# RE01_256KB register map
Vendor: Renesas Electronics Corporation; Series: RE01; File version: 1.00.01
CPU: CM0PLUS r0p1, little endian, MPU, no FPU, VTOR, 2 interrupt priority bits, 32 interrupts
Registers are 8-bit, read-write, reset 0x0 unless marked. A register's access mark holds for its fields unless they carry their own. Offsets are from the block's base; [hi:lo] are bit positions; {n}, {i} and the like mark numbered series; 'fields as' and 'values as' point back to an identical list.

## PORT2 — Port 2 Control Registers
Base 0x40040040
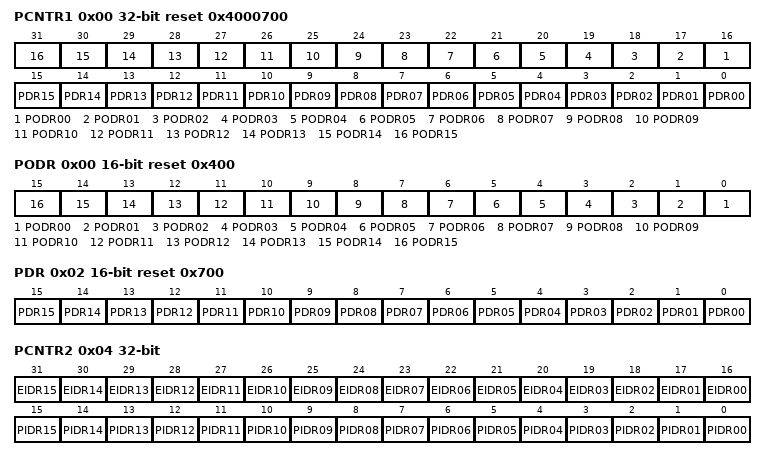
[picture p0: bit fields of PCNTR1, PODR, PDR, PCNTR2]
0x00 PCNTR1 32-bit reset 0x4000700 — Port Control Register 1
  [n+16] PODR{n:02} (n=0..15) — Pmn Output Data Store
    0=Low output; 1=High output
  [n] PDR{n:02} (n=0..15) — Pmn Direction Control
    0=Input (functions as an input pin); 1=Output (functions as an output pin)
0x00 PODR 16-bit reset 0x400 (alternate view of PCNTR1) — Port Control Register 1
  [all] fields
    0=Low output; 1=High output
  [n] PODR{n:02} (n=0..15) — Pmn Output Data Store
0x02 PDR 16-bit reset 0x700 (alternate view of PCNTR1) — Port Control Register 1
  [all] fields
    values as PCNTR1.PDR00
  [n] PDR{n:02} (n=0..15) — Pmn Direction Control
0x04 PCNTR2 32-bit ro reset not defined — Port Control Register 2
  [all] fields
    0=Low input; 1=High input
  [n+16] EIDR{n:02} (n=0..15) — Pmn Event Input Data
  [n] PIDR{n:02} (n=0..15) — Pmn Input Data
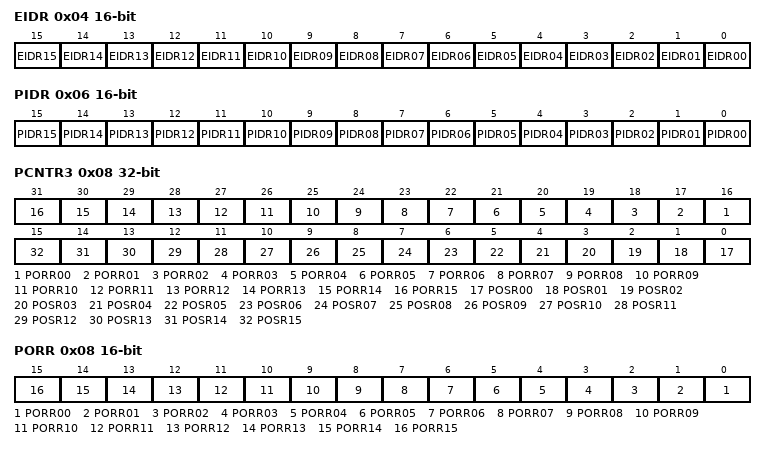
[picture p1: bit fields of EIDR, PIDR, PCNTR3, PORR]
0x04 EIDR 16-bit ro reset not defined (alternate view of PCNTR2) — Port Control Register 2
  [all] fields
    0=Low input; 1=High input
  [n] EIDR{n:02} (n=0..15) — Pmn Event Input Data
0x06 PIDR 16-bit ro reset not defined (alternate view of PCNTR2) — Port Control Register 2
  [all] fields
    0=Low input; 1=High input
  [n] PIDR{n:02} (n=0..15) — Pmn Input Data
0x08 PCNTR3 32-bit wo — Port Control Register 3
  [n+16] PORR{n:02} (n=0..15) — Pmn Output Low Set
    0=No affect on output; 1=Low output
  [n] POSR{n:02} (n=0..15) — Pmn Output High Set
    0=No affect on output; 1=High output
0x08 PORR 16-bit wo (alternate view of PCNTR3) — Port Control Register 3
  [all] fields
    0=No affect on output; 1=Low output
  [n] PORR{n:02} (n=0..15) — Pmn Output Low Set
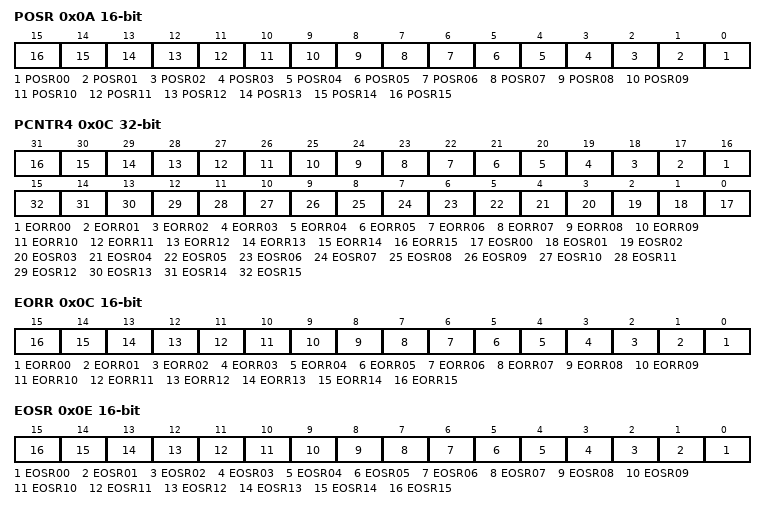
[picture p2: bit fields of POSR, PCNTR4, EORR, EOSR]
0x0A POSR 16-bit wo (alternate view of PCNTR3) — Port Control Register 3
  [all] fields
    0=No affect on output; 1=High output
  [n] POSR{n:02} (n=0..15) — Pmn Output High Set
0x0C PCNTR4 32-bit — Port Control Register 4
  [n+16] EORR{n:02} (n=0..15) — Pmn Event Low Output Set
    0=No affect on output; 1=Low output
  [n] EOSR{n:02} (n=0..15) — Pmn Event High Output Set
    0=No affect on output; 1=High output
0x0C EORR 16-bit (alternate view of PCNTR4) — Port Control Register 4
  [all] fields
    0=No affect on output; 1=Low output
  [n] EORR{n:02} (n=0..15) — Pmn Event Low Output Set
0x0E EOSR 16-bit (alternate view of PCNTR4) — Port Control Register 4
  [all] fields
    0=No affect on output; 1=High output
  [n] EOSR{n:02} (n=0..15) — Pmn Event High Output Set

## PORT3 — Port 3 Control Registers
Base 0x40040060
Registers as PORT2; these are added or differ:
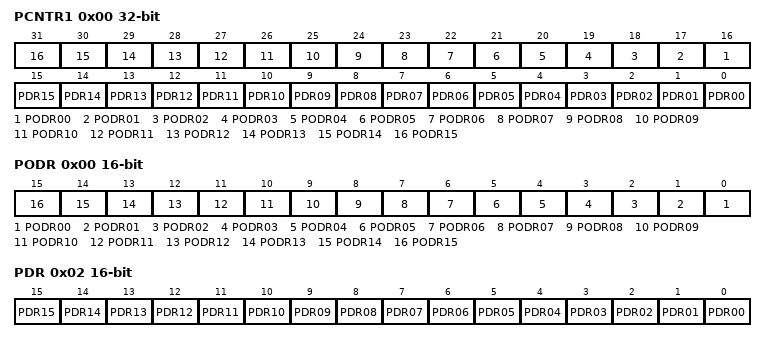
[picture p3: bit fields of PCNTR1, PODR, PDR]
0x00 PCNTR1 32-bit — Port Control Register 1
  fields as PORT2.PCNTR1
0x00 PODR 16-bit (alternate view of PCNTR1) — Port Control Register 1
  [all] fields
    0=Low output; 1=High output
  [n] PODR{n:02} (n=0..15) — Pmn Output Data Store
0x02 PDR 16-bit (alternate view of PCNTR1) — Port Control Register 1
  [all] fields
    0=Input (functions as an input pin); 1=Output (functions as an output pin)
  [n] PDR{n:02} (n=0..15) — Pmn Direction Control

## PORT4 — Port 4 Control Registers
Base 0x40040080
Registers as PORT2, without EIDR, PCNTR4, EORR, EOSR; these are added or differ:
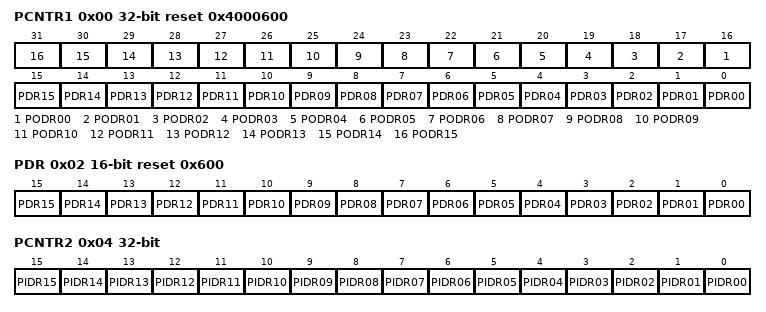
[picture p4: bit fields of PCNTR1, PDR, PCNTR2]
0x00 PCNTR1 32-bit reset 0x4000600 — Port Control Register 1
  fields as PORT2.PCNTR1
0x02 PDR 16-bit reset 0x600 (alternate view of PCNTR1) — Port Control Register 1
  [all] fields
    0=Input (functions as an input pin); 1=Output (functions as an output pin)
  [n] PDR{n:02} (n=0..15) — Pmn Direction Control
0x04 PCNTR2 32-bit ro reset not defined — Port Control Register 2
  [all] fields
    0=Low input; 1=High input
  [n] PIDR{n:02} (n=0..15) — Pmn Input Data

## Notices in the file
This software is supplied by Renesas Electronics Corporation and is only intended for
use with Renesas products. No other uses are authorized. This software is owned by
Renesas Electronics Corporation and is protected under all applicable laws, including
copyright laws.
THIS SOFTWARE IS PROVIDED "AS IS" AND RENESAS MAKES NO WARRANTIES REGARDING
THIS SOFTWARE, WHETHER EXPRESS, IMPLIED OR STATUTORY, INCLUDING BUT NOT LIMITED TO
WARRANTIES OF MERCHANTABILITY, FITNESS FOR A PARTICULAR PURPOSE AND NON-INFRINGEMENT.
ALL SUCH WARRANTIES ARE EXPRESSLY DISCLAIMED. TO THE MAXIMUM EXTENT PERMITTED NOT
PROHIBITED BY LAW, NEITHER RENESAS ELECTRONICS CORPORATION NOR ANY OF ITS AFFILIATED
COMPANIES SHALL BE LIABLE FOR ANY DIRECT, INDIRECT, SPECIAL, INCIDENTAL OR CONSEQUENTIAL
DAMAGES FOR ANY REASON RELATED TO THIS SOFTWARE, EVEN IF RENESAS OR ITS AFFILIATES HAVE
BEEN ADVISED OF THE POSSIBILITY OF SUCH DAMAGES.
Renesas reserves the right, without notice, to make changes to this software and to
discontinue the availability of this software. By using this software, you agree to
the additional terms and conditions found by accessing the following link:
http://www.renesas.com/disclaimer
